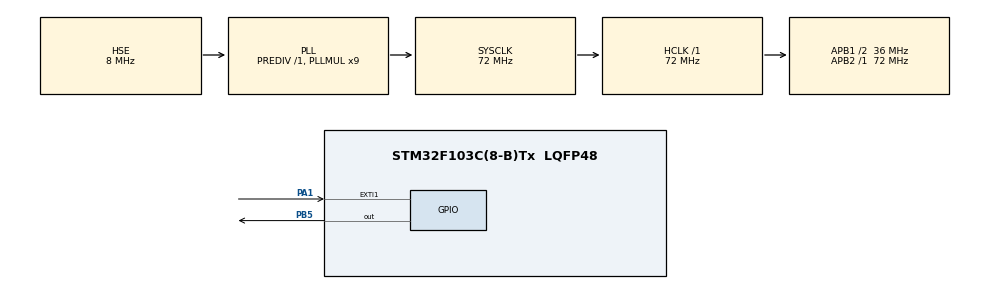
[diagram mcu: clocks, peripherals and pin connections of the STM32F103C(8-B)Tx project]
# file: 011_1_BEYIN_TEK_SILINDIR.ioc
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Mcu.Family=STM32F1
RCC.PLLSourceVirtual=RCC_PLLSOURCE_HSE
PD1-OSC_OUT.Mode=HSE-External-Oscillator
PD0-OSC_IN.Signal=RCC_OSC_IN
RCC.APB1CLKDivider=RCC_HCLK_DIV2
RCC.SYSCLKSource=RCC_SYSCLKSOURCE_PLLCLK
ProjectManager.StackSize=0x400
PD1-OSC_OUT.Signal=RCC_OSC_OUT
PA13.Signal=SYS_JTMS-SWDIO
NVIC.EXTI1_IRQn=true\:0\:0\:false\:false\:true\:true\:true
ProjectManager.TargetToolchain=STM32CubeIDE
RCC.HCLKFreq_Value=72000000
RCC.APB2TimFreq_Value=72000000
RCC.USBFreq_Value=72000000
PA1.GPIO_PuPd=GPIO_NOPULL
PA1.Signal=GPXTI1
RCC.AHBFreq_Value=72000000
PD0-OSC_IN.Mode=HSE-External-Oscillator
board=custom
RCC.PLLMUL=RCC_PLL_MUL9
RCC.APB2Freq_Value=72000000
VP_TIM2_VS_ClockSourceINT.Mode=Internal
PA14.Mode=Serial_Wire
NVIC.TIM2_IRQn=true\:0\:0\:false\:false\:true\:true\:true
TIM2.Period=1999
PA13.Mode=Serial_Wire
Mcu.Name=STM32F103C(8-B)Tx
RCC.SYSCLKFreq_VALUE=72000000
PB5.Signal=GPIO_Output
Mcu.Package=LQFP48
TIM2.Prescaler=35999
PA14.Signal=SYS_JTCK-SWCLK
ProjectManager.HeapSize=0x200
NVIC.PriorityGroup=NVIC_PRIORITYGROUP_4
RCC.APB1TimFreq_Value=72000000
RCC.APB1Freq_Value=36000000
PA1.GPIO_ModeDefaultEXTI=GPIO_MODE_IT_RISING

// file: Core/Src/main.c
/* USER CODE BEGIN Header */
/**
  ******************************************************************************
  * @file           : main.c
  * @brief          : Main program body
  ******************************************************************************
  * @attention
  *
  * <h2><center>&copy; Copyright (c) 2021 STMicroelectronics.
  * All rights reserved.</center></h2>
  *
  * This software component is licensed by ST under BSD 3-Clause license,
  * the "License"; You may not use this file except in compliance with the
  * License. You may obtain a copy of the License at:
  *                        opensource.org/licenses/BSD-3-Clause
  *
  ******************************************************************************
  */
/* USER CODE END Header */
#include "main.h"

/* USER CODE BEGIN Includes */
int disli = 0;
float devir = 0;
int avans =0;

/* USER CODE END Includes */

TIM_HandleTypeDef htim2;

void SystemClock_Config(void);
static void MX_GPIO_Init(void);
static void MX_TIM2_Init(void);
/* USER CODE BEGIN PFP */

void delay(uint32_t time)

{

while(time--);

}

void HAL_TIM_PeriodElapsedCallback(TIM_HandleTypeDef *htim)
{

	devir = disli/11;
	disli = 0;
	//time++;
}

/* USER CODE END PFP */

/* USER CODE BEGIN 0 */

void HAL_GPIO_EXTI_Callback(uint16_t GPIO_Pin)
{
	if(HAL_GPIO_ReadPin(GPIOA, GPIO_PIN_1))
	{

//		avans++;
//		if(avans == 11)
//		{
		HAL_GPIO_WritePin(GPIOB, GPIO_PIN_5, GPIO_PIN_SET);
		delay(900000);
		HAL_GPIO_WritePin(GPIOB, GPIO_PIN_5, GPIO_PIN_RESET);
		delay(9000);
		disli++;
//		avans=0;
//		}

	}
}

/* USER CODE END 0 */

int main(void)
{

  /* MCU Configuration--------------------------------------------------------*/

  /* Reset of all peripherals, Initializes the Flash interface and the Systick. */
  HAL_Init();

  /* Configure the system clock */
  SystemClock_Config();

  /* Initialize all configured peripherals */
  MX_GPIO_Init();
  MX_TIM2_Init();
  /* USER CODE BEGIN 2 */
  HAL_TIM_Base_Start_IT(&htim2);

  /* USER CODE END 2 */

  /* Infinite loop */
  while (1)
  {

    /* USER CODE BEGIN 3 */
//		HAL_GPIO_WritePin(GPIOB, GPIO_PIN_5, GPIO_PIN_SET);
//		HAL_Delay(8000);
//		HAL_GPIO_WritePin(GPIOB, GPIO_PIN_5, GPIO_PIN_RESET);
//		HAL_Delay(8000);

  }
  /* USER CODE END 3 */
}

void SystemClock_Config(void)
{
  RCC_OscInitTypeDef RCC_OscInitStruct = {0};
  RCC_ClkInitTypeDef RCC_ClkInitStruct = {0};

  /** Initializes the RCC Oscillators according to the specified parameters
  * in the RCC_OscInitTypeDef structure.
  */
  RCC_OscInitStruct.OscillatorType = RCC_OSCILLATORTYPE_HSE;
  RCC_OscInitStruct.HSEState = RCC_HSE_ON;
  RCC_OscInitStruct.HSEPredivValue = RCC_HSE_PREDIV_DIV1;
  RCC_OscInitStruct.HSIState = RCC_HSI_ON;
  RCC_OscInitStruct.PLL.PLLState = RCC_PLL_ON;
  RCC_OscInitStruct.PLL.PLLSource = RCC_PLLSOURCE_HSE;
  RCC_OscInitStruct.PLL.PLLMUL = RCC_PLL_MUL9;
  if (HAL_RCC_OscConfig(&RCC_OscInitStruct) != HAL_OK)
  {
    Error_Handler();
  }
  /** Initializes the CPU, AHB and APB buses clocks
  */
  RCC_ClkInitStruct.ClockType = RCC_CLOCKTYPE_HCLK|RCC_CLOCKTYPE_SYSCLK
                              |RCC_CLOCKTYPE_PCLK1|RCC_CLOCKTYPE_PCLK2;
  RCC_ClkInitStruct.SYSCLKSource = RCC_SYSCLKSOURCE_PLLCLK;
  RCC_ClkInitStruct.AHBCLKDivider = RCC_SYSCLK_DIV1;
  RCC_ClkInitStruct.APB1CLKDivider = RCC_HCLK_DIV2;
  RCC_ClkInitStruct.APB2CLKDivider = RCC_HCLK_DIV1;

  if (HAL_RCC_ClockConfig(&RCC_ClkInitStruct, FLASH_LATENCY_2) != HAL_OK)
  {
    Error_Handler();
  }
}

static void MX_TIM2_Init(void)
{

  TIM_ClockConfigTypeDef sClockSourceConfig = {0};
  TIM_MasterConfigTypeDef sMasterConfig = {0};

  htim2.Instance = TIM2;
  htim2.Init.Prescaler = 35999;
  htim2.Init.CounterMode = TIM_COUNTERMODE_UP;
  htim2.Init.Period = 1999;
  htim2.Init.ClockDivision = TIM_CLOCKDIVISION_DIV1;
  htim2.Init.AutoReloadPreload = TIM_AUTORELOAD_PRELOAD_DISABLE;
  if (HAL_TIM_Base_Init(&htim2) != HAL_OK)
  {
    Error_Handler();
  }
  sClockSourceConfig.ClockSource = TIM_CLOCKSOURCE_INTERNAL;
  if (HAL_TIM_ConfigClockSource(&htim2, &sClockSourceConfig) != HAL_OK)
  {
    Error_Handler();
  }
  sMasterConfig.MasterOutputTrigger = TIM_TRGO_RESET;
  sMasterConfig.MasterSlaveMode = TIM_MASTERSLAVEMODE_DISABLE;
  if (HAL_TIMEx_MasterConfigSynchronization(&htim2, &sMasterConfig) != HAL_OK)
  {
    Error_Handler();
  }

}

static void MX_GPIO_Init(void)
{
  GPIO_InitTypeDef GPIO_InitStruct = {0};

  /* GPIO Ports Clock Enable */
  __HAL_RCC_GPIOD_CLK_ENABLE();
  __HAL_RCC_GPIOA_CLK_ENABLE();
  __HAL_RCC_GPIOB_CLK_ENABLE();

  /*Configure GPIO pin Output Level */
  HAL_GPIO_WritePin(GPIOB, GPIO_PIN_5, GPIO_PIN_RESET);

  /*Configure GPIO pin : PA1 */
  GPIO_InitStruct.Pin = GPIO_PIN_1;
  GPIO_InitStruct.Mode = GPIO_MODE_IT_RISING;
  GPIO_InitStruct.Pull = GPIO_NOPULL;
  HAL_GPIO_Init(GPIOA, &GPIO_InitStruct);

  /*Configure GPIO pin : PB5 */
  GPIO_InitStruct.Pin = GPIO_PIN_5;
  GPIO_InitStruct.Mode = GPIO_MODE_OUTPUT_PP;
  GPIO_InitStruct.Pull = GPIO_NOPULL;
  GPIO_InitStruct.Speed = GPIO_SPEED_FREQ_LOW;
  HAL_GPIO_Init(GPIOB, &GPIO_InitStruct);

  /* EXTI interrupt init*/
  HAL_NVIC_SetPriority(EXTI1_IRQn, 0, 0);
  HAL_NVIC_EnableIRQ(EXTI1_IRQn);

}

void Error_Handler(void)
{
  __disable_irq();
  while (1)
  {
  }
}

/************************ (C) COPYRIGHT STMicroelectronics *****END OF FILE****/
